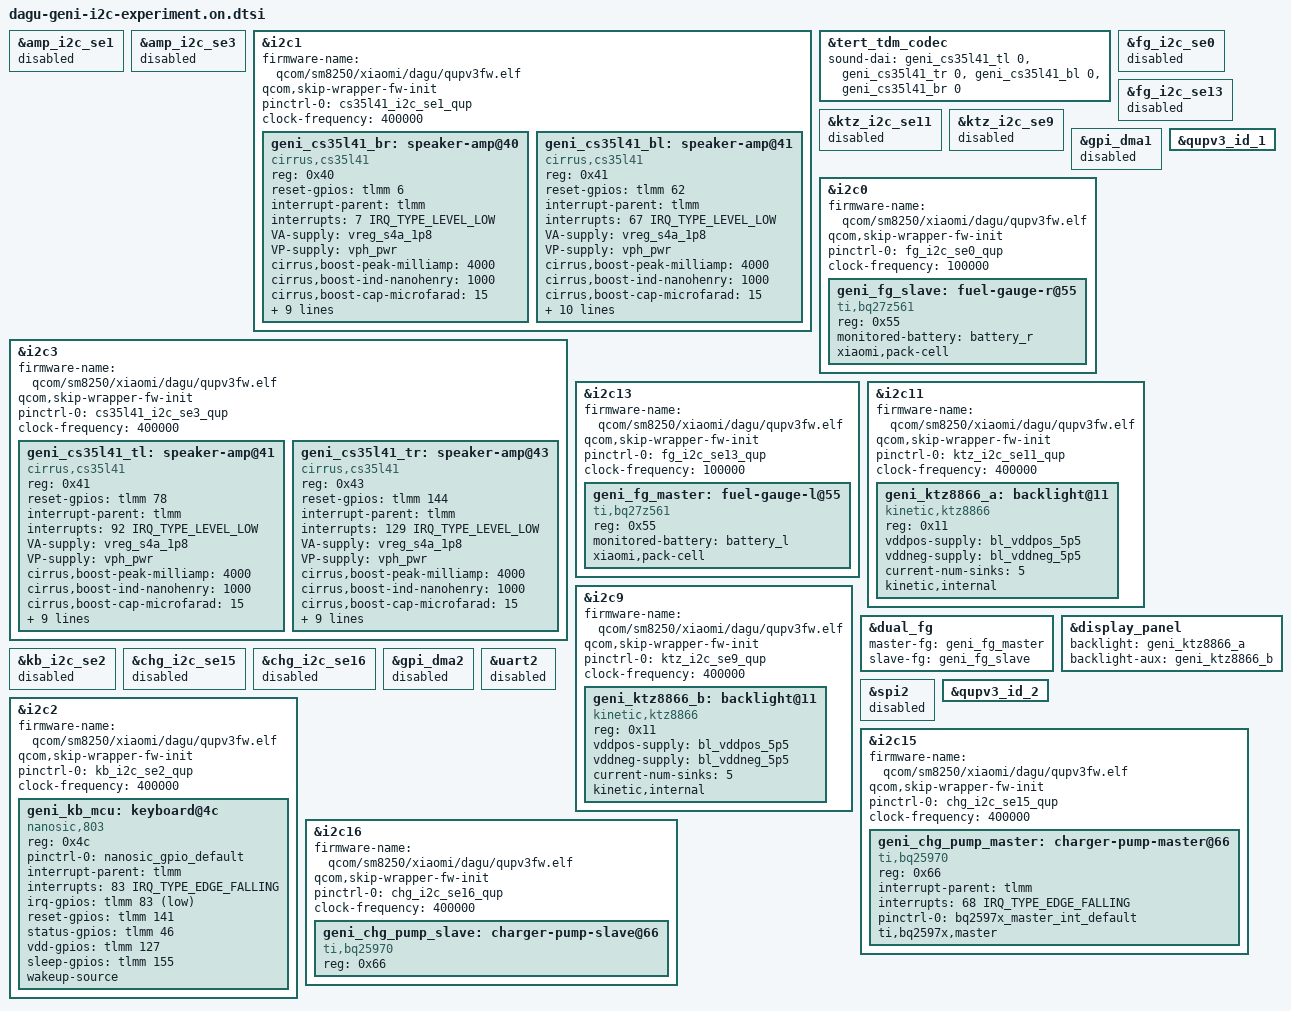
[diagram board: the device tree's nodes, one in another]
/*
 * Product: CS35L41 SE1/SE3, BQ27Z561 SE0/SE13, KTZ8866 SE11/SE9,
 * Nanosic SE2, BQ25970 SE15/SE16. Per-SE IRAM like uart6.
 * Do not put firmware-name on &qupv3_id_0 / _1 / _2. Do not enable GPI DMA.
 * uart2/spi2 stay off (same SE MMIO as i2c2). Failure: restore-a.
 */
&amp_i2c_se1 { status = "disabled"; };
&amp_i2c_se3 { status = "disabled"; };

&i2c1 {
	/delete-property/ interconnects;
	/delete-property/ interconnect-names;
	/delete-property/ dmas;
	/delete-property/ dma-names;
	firmware-name = "qcom/sm8250/xiaomi/dagu/qupv3fw.elf";
	qcom,skip-wrapper-fw-init;
	pinctrl-names = "default";
	pinctrl-0 = <&cs35l41_i2c_se1_qup>;
	clock-frequency = <400000>;
	status = "okay";

	geni_cs35l41_br: speaker-amp@40 {
		compatible = "cirrus,cs35l41";
		reg = <0x40>;
		reset-gpios = <&tlmm 6 GPIO_ACTIVE_HIGH>;
		interrupt-parent = <&tlmm>;
		interrupts = <7 IRQ_TYPE_LEVEL_LOW>;
		VA-supply = <&vreg_s4a_1p8>;
		VP-supply = <&vph_pwr>;
		cirrus,boost-peak-milliamp = <4000>;
		cirrus,boost-ind-nanohenry = <1000>;
		cirrus,boost-cap-microfarad = <15>;
		cirrus,asp-sdout-hiz = <3>;
		cirrus,gpio2-src-select = <4>;
		cirrus,gpio2-output-enable;
		cirrus,subsystem-id = "dagu";
		cirrus,fast-switch = "cirrus/BR-music.txt";
		cirrus,cal-r = <9696>;
		cirrus,cal-ambient = <23>;
		cirrus,vpbr-config = <33575690>;
		sound-name-prefix = "BR";
		#sound-dai-cells = <1>;
	};

	geni_cs35l41_bl: speaker-amp@41 {
		compatible = "cirrus,cs35l41";
		reg = <0x41>;
		reset-gpios = <&tlmm 62 GPIO_ACTIVE_HIGH>;
		interrupt-parent = <&tlmm>;
		interrupts = <67 IRQ_TYPE_LEVEL_LOW>;
		VA-supply = <&vreg_s4a_1p8>;
		VP-supply = <&vph_pwr>;
		cirrus,boost-peak-milliamp = <4000>;
		cirrus,boost-ind-nanohenry = <1000>;
		cirrus,boost-cap-microfarad = <15>;
		cirrus,asp-sdout-hiz = <3>;
		cirrus,gpio2-src-select = <4>;
		cirrus,gpio2-output-enable;
		cirrus,right-channel-amp;
		cirrus,subsystem-id = "dagu";
		cirrus,fast-switch = "cirrus/BL-music.txt";
		cirrus,cal-r = <9497>;
		cirrus,cal-ambient = <23>;
		cirrus,vpbr-config = <33575690>;
		sound-name-prefix = "BL";
		#sound-dai-cells = <1>;
	};
};

&i2c3 {
	/delete-property/ interconnects;
	/delete-property/ interconnect-names;
	/delete-property/ dmas;
	/delete-property/ dma-names;
	firmware-name = "qcom/sm8250/xiaomi/dagu/qupv3fw.elf";
	qcom,skip-wrapper-fw-init;
	pinctrl-names = "default";
	pinctrl-0 = <&cs35l41_i2c_se3_qup>;
	clock-frequency = <400000>;
	status = "okay";

	geni_cs35l41_tl: speaker-amp@41 {
		compatible = "cirrus,cs35l41";
		reg = <0x41>;
		reset-gpios = <&tlmm 78 GPIO_ACTIVE_HIGH>;
		interrupt-parent = <&tlmm>;
		interrupts = <92 IRQ_TYPE_LEVEL_LOW>;
		VA-supply = <&vreg_s4a_1p8>;
		VP-supply = <&vph_pwr>;
		cirrus,boost-peak-milliamp = <4000>;
		cirrus,boost-ind-nanohenry = <1000>;
		cirrus,boost-cap-microfarad = <15>;
		cirrus,asp-sdout-hiz = <3>;
		cirrus,gpio2-src-select = <4>;
		cirrus,gpio2-output-enable;
		cirrus,subsystem-id = "dagu";
		cirrus,fast-switch = "cirrus/TL-music.txt";
		cirrus,cal-r = <9524>;
		cirrus,cal-ambient = <23>;
		cirrus,vpbr-config = <33575689>;
		sound-name-prefix = "TL";
		#sound-dai-cells = <1>;
	};

	geni_cs35l41_tr: speaker-amp@43 {
		compatible = "cirrus,cs35l41";
		reg = <0x43>;
		reset-gpios = <&tlmm 144 GPIO_ACTIVE_HIGH>;
		interrupt-parent = <&tlmm>;
		interrupts = <129 IRQ_TYPE_LEVEL_LOW>;
		VA-supply = <&vreg_s4a_1p8>;
		VP-supply = <&vph_pwr>;
		cirrus,boost-peak-milliamp = <4000>;
		cirrus,boost-ind-nanohenry = <1000>;
		cirrus,boost-cap-microfarad = <15>;
		cirrus,asp-sdout-hiz = <3>;
		cirrus,gpio2-src-select = <4>;
		cirrus,gpio2-output-enable;
		cirrus,subsystem-id = "dagu";
		cirrus,fast-switch = "cirrus/TR-music.txt";
		cirrus,cal-r = <9632>;
		cirrus,cal-ambient = <23>;
		cirrus,vpbr-config = <33575689>;
		sound-name-prefix = "TR";
		#sound-dai-cells = <1>;
	};
};

&tert_tdm_codec {
	sound-dai = <&geni_cs35l41_tl 0>, <&geni_cs35l41_tr 0>,
		    <&geni_cs35l41_bl 0>, <&geni_cs35l41_br 0>;
};

&fg_i2c_se0 { status = "disabled"; };
&fg_i2c_se13 { status = "disabled"; };
&ktz_i2c_se11 { status = "disabled"; };
&ktz_i2c_se9 { status = "disabled"; };

/*
 * QUP1 AHB only. ABL already programmed the wrapper; never firmware-name here.
 * gpi_dma1 stays off — I2C FIFO, same as CS35L41 on QUP0.
 */
&gpi_dma1 { status = "disabled"; };
&qupv3_id_1 { status = "okay"; };

&i2c0 {
	/delete-property/ interconnects;
	/delete-property/ interconnect-names;
	/delete-property/ dmas;
	/delete-property/ dma-names;
	firmware-name = "qcom/sm8250/xiaomi/dagu/qupv3fw.elf";
	qcom,skip-wrapper-fw-init;
	pinctrl-names = "default";
	pinctrl-0 = <&fg_i2c_se0_qup>;
	clock-frequency = <100000>;
	status = "okay";
	/delete-node/ fuel-gauge@55;

	geni_fg_slave: fuel-gauge-r@55 {
		compatible = "ti,bq27z561";
		reg = <0x55>;
		monitored-battery = <&battery_r>;
		xiaomi,pack-cell;
	};
};

&i2c13 {
	/delete-property/ interconnects;
	/delete-property/ interconnect-names;
	/delete-property/ dmas;
	/delete-property/ dma-names;
	firmware-name = "qcom/sm8250/xiaomi/dagu/qupv3fw.elf";
	qcom,skip-wrapper-fw-init;
	pinctrl-names = "default";
	pinctrl-0 = <&fg_i2c_se13_qup>;
	clock-frequency = <100000>;
	status = "okay";
	/delete-node/ fuel-gauge@55;

	geni_fg_master: fuel-gauge-l@55 {
		compatible = "ti,bq27z561";
		reg = <0x55>;
		monitored-battery = <&battery_l>;
		xiaomi,pack-cell;
	};
};

&i2c11 {
	/delete-property/ interconnects;
	/delete-property/ interconnect-names;
	/delete-property/ dmas;
	/delete-property/ dma-names;
	firmware-name = "qcom/sm8250/xiaomi/dagu/qupv3fw.elf";
	qcom,skip-wrapper-fw-init;
	pinctrl-names = "default";
	pinctrl-0 = <&ktz_i2c_se11_qup>;
	clock-frequency = <400000>;
	status = "okay";
	/delete-node/ backlight@11;

	geni_ktz8866_a: backlight@11 {
		compatible = "kinetic,ktz8866";
		reg = <0x11>;
		vddpos-supply = <&bl_vddpos_5p5>;
		vddneg-supply = <&bl_vddneg_5p5>;
		current-num-sinks = <5>;
		kinetic,internal;
	};
};

&i2c9 {
	/delete-property/ interconnects;
	/delete-property/ interconnect-names;
	/delete-property/ dmas;
	/delete-property/ dma-names;
	firmware-name = "qcom/sm8250/xiaomi/dagu/qupv3fw.elf";
	qcom,skip-wrapper-fw-init;
	pinctrl-names = "default";
	pinctrl-0 = <&ktz_i2c_se9_qup>;
	clock-frequency = <400000>;
	status = "okay";

	geni_ktz8866_b: backlight@11 {
		compatible = "kinetic,ktz8866";
		reg = <0x11>;
		vddpos-supply = <&bl_vddpos_5p5>;
		vddneg-supply = <&bl_vddneg_5p5>;
		current-num-sinks = <5>;
		kinetic,internal;
	};
};

&dual_fg {
	master-fg = <&geni_fg_master>;
	slave-fg = <&geni_fg_slave>;
};

&display_panel {
	backlight = <&geni_ktz8866_a>;
	backlight-aux = <&geni_ktz8866_b>;
};

&kb_i2c_se2 { status = "disabled"; };
&chg_i2c_se15 { status = "disabled"; };
&chg_i2c_se16 { status = "disabled"; };

/*
 * QUP2 AHB only. Never firmware-name on the wrapper. gpi_dma2 off.
 * SE2 is I2C only: uart2/spi2 share 0x988000 with &i2c2.
 */
&gpi_dma2 { status = "disabled"; };
&uart2 { status = "disabled"; };
&spi2 { status = "disabled"; };
&qupv3_id_2 { status = "okay"; };

&i2c2 {
	/delete-property/ interconnects;
	/delete-property/ interconnect-names;
	/delete-property/ dmas;
	/delete-property/ dma-names;
	firmware-name = "qcom/sm8250/xiaomi/dagu/qupv3fw.elf";
	qcom,skip-wrapper-fw-init;
	pinctrl-names = "default";
	pinctrl-0 = <&kb_i2c_se2_qup>;
	clock-frequency = <400000>;
	status = "okay";

	geni_kb_mcu: keyboard@4c {
		compatible = "nanosic,803";
		reg = <0x4c>;
		pinctrl-names = "default";
		pinctrl-0 = <&nanosic_gpio_default>;
		interrupt-parent = <&tlmm>;
		interrupts = <83 IRQ_TYPE_EDGE_FALLING>;
		irq-gpios = <&tlmm 83 GPIO_ACTIVE_LOW>;
		reset-gpios = <&tlmm 141 GPIO_ACTIVE_HIGH>;
		status-gpios = <&tlmm 46 GPIO_ACTIVE_HIGH>;
		vdd-gpios = <&tlmm 127 GPIO_ACTIVE_HIGH>;
		sleep-gpios = <&tlmm 155 GPIO_ACTIVE_HIGH>;
		wakeup-source;
	};
};

&i2c15 {
	/delete-property/ interconnects;
	/delete-property/ interconnect-names;
	/delete-property/ dmas;
	/delete-property/ dma-names;
	firmware-name = "qcom/sm8250/xiaomi/dagu/qupv3fw.elf";
	qcom,skip-wrapper-fw-init;
	pinctrl-names = "default";
	pinctrl-0 = <&chg_i2c_se15_qup>;
	clock-frequency = <400000>;
	status = "okay";

	geni_chg_pump_master: charger-pump-master@66 {
		compatible = "ti,bq25970";
		reg = <0x66>;
		interrupt-parent = <&tlmm>;
		interrupts = <68 IRQ_TYPE_EDGE_FALLING>;
		pinctrl-names = "default";
		pinctrl-0 = <&bq2597x_master_int_default>;
		ti,bq2597x,master;
	};
};

&i2c16 {
	/delete-property/ interconnects;
	/delete-property/ interconnect-names;
	/delete-property/ dmas;
	/delete-property/ dma-names;
	firmware-name = "qcom/sm8250/xiaomi/dagu/qupv3fw.elf";
	qcom,skip-wrapper-fw-init;
	pinctrl-names = "default";
	pinctrl-0 = <&chg_i2c_se16_qup>;
	clock-frequency = <400000>;
	status = "okay";

	geni_chg_pump_slave: charger-pump-slave@66 {
		compatible = "ti,bq25970";
		reg = <0x66>;
	};
};
